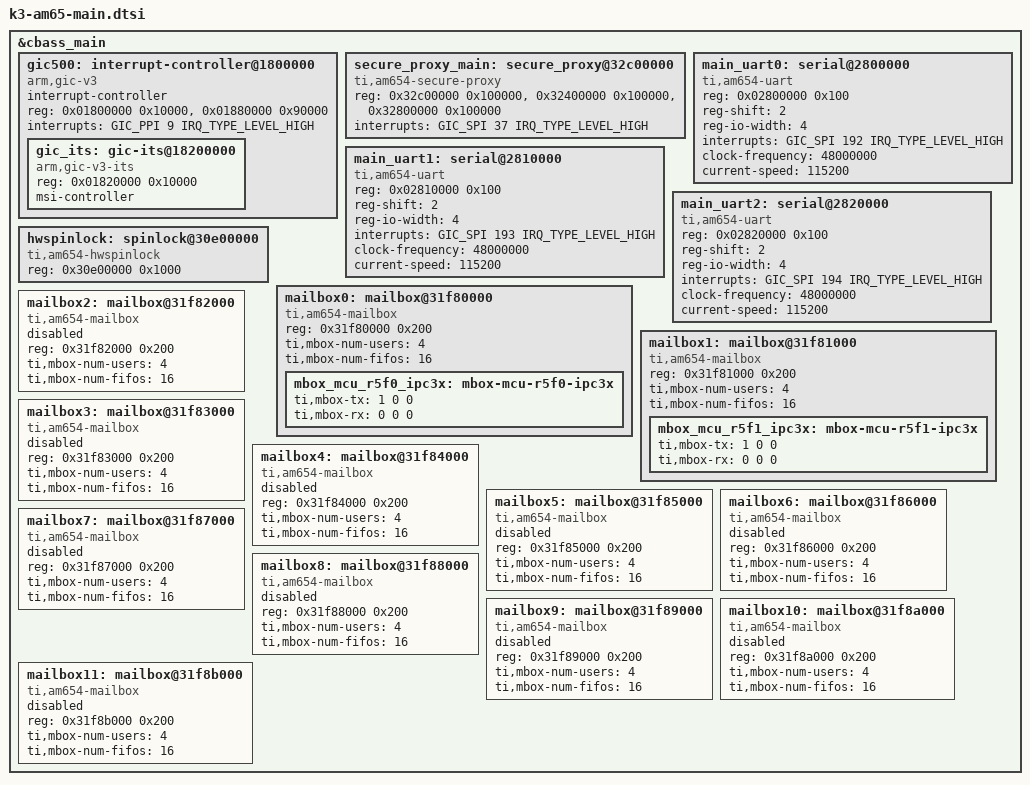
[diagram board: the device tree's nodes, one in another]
// SPDX-License-Identifier: GPL-2.0
/*
 * Device Tree Source for AM6 SoC Family Main Domain peripherals
 *
 * Copyright (C) 2016-2018 Texas Instruments Incorporated - http://www.ti.com/
 */

&cbass_main {
	gic500: interrupt-controller@1800000 {
		compatible = "arm,gic-v3";
		#address-cells = <1>;
		#size-cells = <1>;
		ranges;
		#interrupt-cells = <3>;
		interrupt-controller;
		reg = <0x01800000 0x10000>,	/* GICD */
		      <0x01880000 0x90000>;	/* GICR */
		/*
		 * vcpumntirq:
		 * virtual CPU interface maintenance interrupt
		 */
		interrupts = <GIC_PPI 9 IRQ_TYPE_LEVEL_HIGH>;

		gic_its: gic-its@18200000 {
			compatible = "arm,gic-v3-its";
			reg = <0x01820000 0x10000>;
			msi-controller;
			#msi-cells = <1>;
		};
	};

	secure_proxy_main: secure_proxy@32c00000 {
		compatible = "ti,am654-secure-proxy";
		#mbox-cells = <1>;
		reg-names = "target_data", "rt", "scfg";
		reg = <0x32c00000 0x100000>,
		      <0x32400000 0x100000>,
		      <0x32800000 0x100000>;
		interrupt-names = "rx_011";
		interrupts = <GIC_SPI 37 IRQ_TYPE_LEVEL_HIGH>;
	};

	main_uart0: serial@2800000 {
		compatible = "ti,am654-uart";
		reg = <0x02800000 0x100>;
		reg-shift = <2>;
		reg-io-width = <4>;
		interrupts = <GIC_SPI 192 IRQ_TYPE_LEVEL_HIGH>;
		clock-frequency = <48000000>;
		current-speed = <115200>;
	};

	main_uart1: serial@2810000 {
		compatible = "ti,am654-uart";
		reg = <0x02810000 0x100>;
		reg-shift = <2>;
		reg-io-width = <4>;
		interrupts = <GIC_SPI 193 IRQ_TYPE_LEVEL_HIGH>;
		clock-frequency = <48000000>;
		current-speed = <115200>;
	};

	main_uart2: serial@2820000 {
		compatible = "ti,am654-uart";
		reg = <0x02820000 0x100>;
		reg-shift = <2>;
		reg-io-width = <4>;
		interrupts = <GIC_SPI 194 IRQ_TYPE_LEVEL_HIGH>;
		clock-frequency = <48000000>;
		current-speed = <115200>;
	};

	hwspinlock: spinlock@30e00000 {
		compatible = "ti,am654-hwspinlock";
		reg = <0x30e00000 0x1000>;
		#hwlock-cells = <1>;
	};

	mailbox0: mailbox@31f80000 {
		compatible = "ti,am654-mailbox";
		reg = <0x31f80000 0x200>;
		#mbox-cells = <1>;
		ti,mbox-num-users = <4>;
		ti,mbox-num-fifos = <16>;
		/* interrupt-parent = <&k3_irq>; */
		/* interrupts = <164 0 IRQ_TYPE_LEVEL_HIGH>; */

		mbox_mcu_r5f0_ipc3x: mbox-mcu-r5f0-ipc3x {
			ti,mbox-tx = <1 0 0>;
			ti,mbox-rx = <0 0 0>;
		};
	};

	mailbox1: mailbox@31f81000 {
		compatible = "ti,am654-mailbox";
		reg = <0x31f81000 0x200>;
		#mbox-cells = <1>;
		ti,mbox-num-users = <4>;
		ti,mbox-num-fifos = <16>;
		/* interrupt-parent = <&k3_irq>; */
		/* interrupts = <165 0 IRQ_TYPE_LEVEL_HIGH>; */

		mbox_mcu_r5f1_ipc3x: mbox-mcu-r5f1-ipc3x {
			ti,mbox-tx = <1 0 0>;
			ti,mbox-rx = <0 0 0>;
		};
	};

	mailbox2: mailbox@31f82000 {
		compatible = "ti,am654-mailbox";
		reg = <0x31f82000 0x200>;
		#mbox-cells = <1>;
		ti,mbox-num-users = <4>;
		ti,mbox-num-fifos = <16>;
		status = "disabled";
	};

	mailbox3: mailbox@31f83000 {
		compatible = "ti,am654-mailbox";
		reg = <0x31f83000 0x200>;
		#mbox-cells = <1>;
		ti,mbox-num-users = <4>;
		ti,mbox-num-fifos = <16>;
		status = "disabled";
	};

	mailbox4: mailbox@31f84000 {
		compatible = "ti,am654-mailbox";
		reg = <0x31f84000 0x200>;
		#mbox-cells = <1>;
		ti,mbox-num-users = <4>;
		ti,mbox-num-fifos = <16>;
		status = "disabled";
	};

	mailbox5: mailbox@31f85000 {
		compatible = "ti,am654-mailbox";
		reg = <0x31f85000 0x200>;
		#mbox-cells = <1>;
		ti,mbox-num-users = <4>;
		ti,mbox-num-fifos = <16>;
		status = "disabled";
	};

	mailbox6: mailbox@31f86000 {
		compatible = "ti,am654-mailbox";
		reg = <0x31f86000 0x200>;
		#mbox-cells = <1>;
		ti,mbox-num-users = <4>;
		ti,mbox-num-fifos = <16>;
		status = "disabled";
	};

	mailbox7: mailbox@31f87000 {
		compatible = "ti,am654-mailbox";
		reg = <0x31f87000 0x200>;
		#mbox-cells = <1>;
		ti,mbox-num-users = <4>;
		ti,mbox-num-fifos = <16>;
		status = "disabled";
	};

	mailbox8: mailbox@31f88000 {
		compatible = "ti,am654-mailbox";
		reg = <0x31f88000 0x200>;
		#mbox-cells = <1>;
		ti,mbox-num-users = <4>;
		ti,mbox-num-fifos = <16>;
		status = "disabled";
	};

	mailbox9: mailbox@31f89000 {
		compatible = "ti,am654-mailbox";
		reg = <0x31f89000 0x200>;
		#mbox-cells = <1>;
		ti,mbox-num-users = <4>;
		ti,mbox-num-fifos = <16>;
		status = "disabled";
	};

	mailbox10: mailbox@31f8a000 {
		compatible = "ti,am654-mailbox";
		reg = <0x31f8a000 0x200>;
		#mbox-cells = <1>;
		ti,mbox-num-users = <4>;
		ti,mbox-num-fifos = <16>;
		status = "disabled";
	};

	mailbox11: mailbox@31f8b000 {
		compatible = "ti,am654-mailbox";
		reg = <0x31f8b000 0x200>;
		#mbox-cells = <1>;
		ti,mbox-num-users = <4>;
		ti,mbox-num-fifos = <16>;
		status = "disabled";
	};
};
